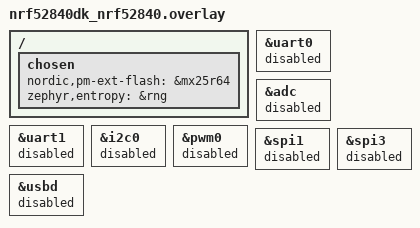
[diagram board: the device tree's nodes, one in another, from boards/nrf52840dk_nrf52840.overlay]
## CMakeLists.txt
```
#
# Copyright (c) 2021 Nordic Semiconductor ASA
#
# SPDX-License-Identifier: LicenseRef-Nordic-5-Clause
#

cmake_minimum_required(VERSION 3.20.0)

find_package(Zephyr HINTS $ENV{ZEPHYR_BASE})

project(nrf52840_icd)

# Enable GNU STD support and initialize the Matter Data Model.
include(${ZEPHYR_CONNECTEDHOMEIP_MODULE_DIR}/config/nrfconnect/app/enable-gnu-std.cmake)
include(${ZEPHYR_CONNECTEDHOMEIP_MODULE_DIR}/src/app/chip_data_model.cmake)

# NORDIC SDK APP START

# Include all source files that are located in the Matter common directory.
include(${ZEPHYR_NRF_MODULE_DIR}/samples/matter/common/cmake/source_common.cmake)

target_include_directories(app PRIVATE
    src
    ${CONFIG_NCS_SAMPLE_MATTER_ZAP_FILES_PATH}
)

target_sources(app PRIVATE
    src/app_task.cpp
    src/main.cpp
)

chip_configure_data_model(app
    INCLUDE_SERVER
    BYPASS_IDL
    GEN_DIR ${CONFIG_NCS_SAMPLE_MATTER_ZAP_FILES_PATH}/zap-generated
    ZAP_FILE ${CMAKE_CURRENT_SOURCE_DIR}/${CONFIG_NCS_SAMPLE_MATTER_ZAP_FILES_PATH}/template.zap
)
# NORDIC SDK APP END
```

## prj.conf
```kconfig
#
# Copyright (c) 2021 Nordic Semiconductor ASA
#
# SPDX-License-Identifier: LicenseRef-Nordic-5-Clause
#

# This sample uses Kconfig.defaults to set options common for all
# samples. This file should contain only options specific for this sample
# or overrides of default values.

# Enable CHIP
CONFIG_CHIP=y
CONFIG_CHIP_PROJECT_CONFIG="src/chip_project_config.h"
# 32768 == 0x8000 (example Product ID added temporaly,
# but it must be changed with proper PID from the list:
# https://github.com/project-chip/connectedhomeip/blob/482e6fd03196a6de45465a90003947ef4b86e0b1/docs/examples/discussion/PID_allocation_for_example_apps.md)
CONFIG_CHIP_DEVICE_PRODUCT_ID=32768
CONFIG_STD_CPP17=y

# Enable Matter pairing automatically on application start.
CONFIG_CHIP_ENABLE_PAIRING_AUTOSTART=y

# Enable Matter extended announcement and increase duration to 1 hour.
CONFIG_CHIP_BLE_EXT_ADVERTISING=y
CONFIG_CHIP_BLE_ADVERTISING_DURATION=60

# Add support for LEDs and buttons on Nordic development kits
CONFIG_DK_LIBRARY=n

# Bluetooth Low Energy configuration
CONFIG_BT_DEVICE_NAME="MatterTemplate"

# Other settings
CONFIG_THREAD_NAME=y
CONFIG_MPU_STACK_GUARD=y
CONFIG_RESET_ON_FATAL_ERROR=n
CONFIG_CHIP_LIB_SHELL=y
CONFIG_NCS_SAMPLE_MATTER_TEST_SHELL=y

# Disable NFC commissioning
CONFIG_CHIP_NFC_COMMISSIONING=n

# Reduce application size
CONFIG_USE_SEGGER_RTT=n

# Enable Factory Data feature
CONFIG_CHIP_FACTORY_DATA=y
CONFIG_CHIP_FACTORY_DATA_BUILD=y

# Thread MTD를 Sleepy End Device로
CONFIG_OPENTHREAD_MTD=y
CONFIG_OPENTHREAD_NORDIC_LIBRARY_MTD=y

# Matter ICD (SIT)
CONFIG_CHIP_ENABLE_ICD_SUPPORT=y
CONFIG_CHIP_ICD_SLOW_POLL_INTERVAL=5000

# Disable UART Log
CONFIG_LOG=n

# disable LEDs
CONFIG_NCS_SAMPLE_MATTER_LEDS=n

CONFIG_PM_DEVICE=y

CONFIG_RAM_POWER_DOWN_LIBRARY=y
```

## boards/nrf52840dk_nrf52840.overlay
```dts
/* Copyright (c) 2021 Nordic Semiconductor ASA
 *
 * SPDX-License-Identifier: LicenseRef-Nordic-5-Clause
 */

/ {
	chosen {
		nordic,pm-ext-flash = &mx25r64;
	};
};


/ {
	/*
	* In some default configurations within the nRF Connect SDK,
	* e.g. on nRF52840, the chosen zephyr,entropy node is &cryptocell.
	* This devicetree overlay ensures that default is overridden wherever it
	* is set, as this application uses the RNG node for entropy exclusively.
	*/
	chosen {
		zephyr,entropy = &rng;
	};
};

/* Disable unused peripherals to reduce power consumption */
&uart0 {
    status = "disabled";
};
&adc {
	status = "disabled";
};
&uart1 {
	status = "disabled";
};
&i2c0 {
	status = "disabled";
};
&pwm0 {
	status = "disabled";
};
&spi1 {
	status = "disabled";
};
&spi3 {
	status = "disabled";
};
&usbd {
	status = "disabled";
};
```

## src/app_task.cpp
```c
/*
 * Copyright (c) 2021 Nordic Semiconductor ASA
 *
 * SPDX-License-Identifier: LicenseRef-Nordic-5-Clause
 */

#include "app_task.h"

#include "app/matter_init.h"
#include "app/task_executor.h"
#include "board/board.h"
#include "lib/core/CHIPError.h"
#include "lib/support/CodeUtils.h"

#include <setup_payload/OnboardingCodesUtil.h>

#include <zephyr/logging/log.h>

#include <zephyr/pm/device.h>

LOG_MODULE_DECLARE(app, CONFIG_CHIP_APP_LOG_LEVEL);

using namespace ::chip;
using namespace ::chip::app;
using namespace ::chip::DeviceLayer;

CHIP_ERROR AppTask::Init()
{
	/* Initialize Matter stack */
	ReturnErrorOnFailure(Nrf::Matter::PrepareServer());

	if (!Nrf::GetBoard().Init()) {
		LOG_ERR("User interface initialization failed.");
		return CHIP_ERROR_INCORRECT_STATE;
	}

	/* Register Matter event handler that controls the connectivity status LED based on the captured Matter network
	 * state. */
	ReturnErrorOnFailure(Nrf::Matter::RegisterEventHandler(Nrf::Board::DefaultMatterEventHandler, 0));

	return Nrf::Matter::StartServer();
}



CHIP_ERROR AppTask::StartApp()
{
	ReturnErrorOnFailure(Init());

    const auto * qspi_dev = DEVICE_DT_GET(DT_INST(0, nordic_qspi_nor));
	if (device_is_ready(qspi_dev))
	{
		// Put the peripheral into suspended state.
		pm_device_action_run(qspi_dev, PM_DEVICE_ACTION_SUSPEND);
	}

	while (true) {
		Nrf::DispatchNextTask();
	}

	return CHIP_NO_ERROR;
}
```
